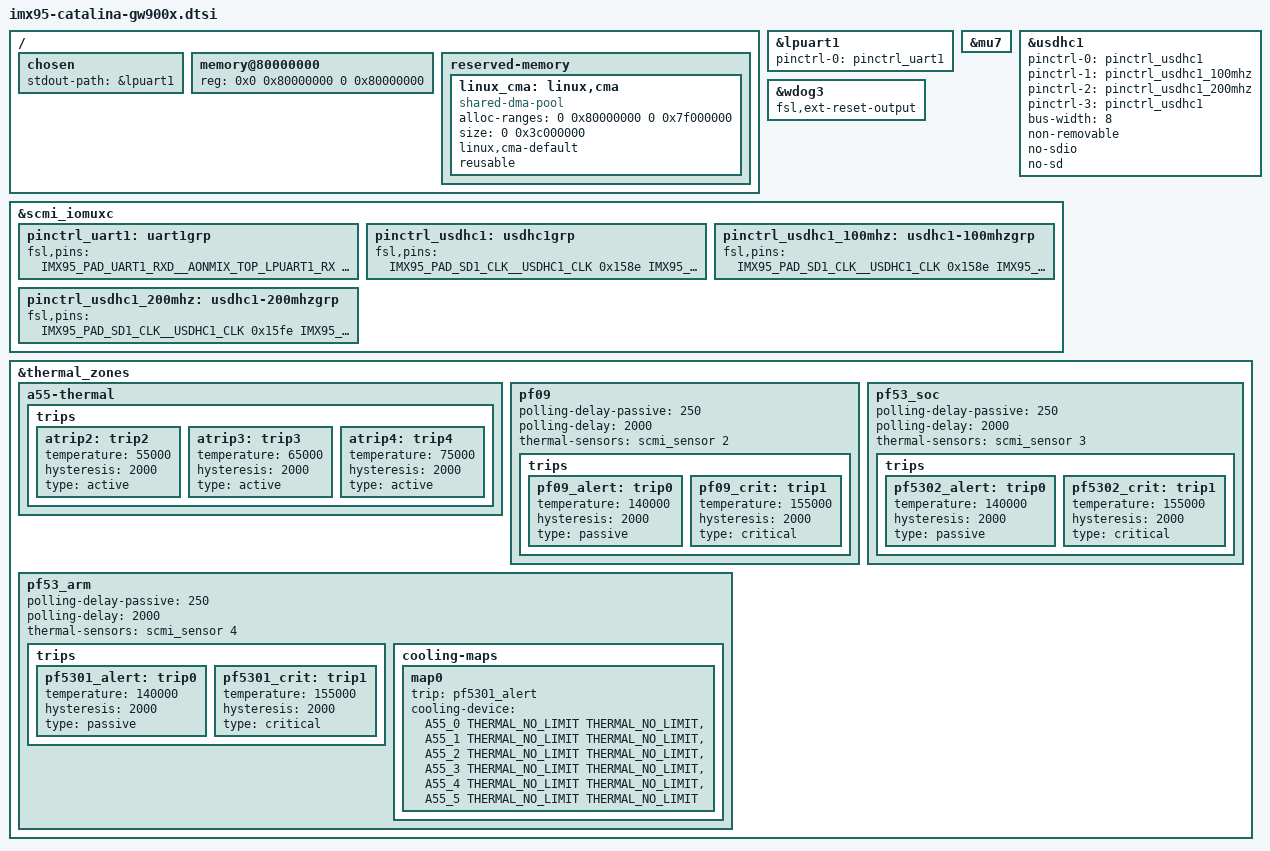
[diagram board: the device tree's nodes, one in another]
// SPDX-License-Identifier: (GPL-2.0+ OR MIT)
/*
 * Copyright 2025 Gateworks Corporation
 */

/ {
	chosen {
		stdout-path = &lpuart1;
	};

	memory@80000000 {
		device_type = "memory";
		reg = <0x0 0x80000000 0 0x80000000>;
	};

	reserved-memory {
		#address-cells = <2>;
		#size-cells = <2>;
		ranges;

		linux_cma: linux,cma {
			compatible = "shared-dma-pool";
			alloc-ranges = <0 0x80000000 0 0x7f000000>;
			size = <0 0x3c000000>;
			linux,cma-default;
			reusable;
		};
	};
};

/* console */
&lpuart1 {
	pinctrl-names = "default";
	pinctrl-0 = <&pinctrl_uart1>;
	status = "okay";
};

&mu7 {
	status = "okay";
};

/* eMMC */
&usdhc1 {
	pinctrl-names = "default", "state_100mhz", "state_200mhz", "sleep";
	pinctrl-0 = <&pinctrl_usdhc1>;
	pinctrl-1 = <&pinctrl_usdhc1_100mhz>;
	pinctrl-2 = <&pinctrl_usdhc1_200mhz>;
	pinctrl-3 = <&pinctrl_usdhc1>;
	bus-width = <8>;
	non-removable;
	no-sdio;
	no-sd;
	status = "okay";
};

&wdog3 {
	fsl,ext-reset-output;
	status = "okay";
};

&scmi_iomuxc {
	pinctrl_uart1: uart1grp {
		fsl,pins = <
			IMX95_PAD_UART1_RXD__AONMIX_TOP_LPUART1_RX      0x31e
			IMX95_PAD_UART1_TXD__AONMIX_TOP_LPUART1_TX      0x31e
		>;
	};

	pinctrl_usdhc1: usdhc1grp {
		fsl,pins = <
			IMX95_PAD_SD1_CLK__USDHC1_CLK			0x158e
			IMX95_PAD_SD1_CMD__USDHC1_CMD			0x138e
			IMX95_PAD_SD1_DATA0__USDHC1_DATA0		0x138e
			IMX95_PAD_SD1_DATA1__USDHC1_DATA1		0x138e
			IMX95_PAD_SD1_DATA2__USDHC1_DATA2		0x138e
			IMX95_PAD_SD1_DATA3__USDHC1_DATA3		0x138e
			IMX95_PAD_SD1_DATA4__USDHC1_DATA4		0x138e
			IMX95_PAD_SD1_DATA5__USDHC1_DATA5		0x138e
			IMX95_PAD_SD1_DATA6__USDHC1_DATA6		0x138e
			IMX95_PAD_SD1_DATA7__USDHC1_DATA7		0x138e
			IMX95_PAD_SD1_STROBE__USDHC1_STROBE		0x158e
		>;
	};

	pinctrl_usdhc1_100mhz: usdhc1-100mhzgrp {
		fsl,pins = <
			IMX95_PAD_SD1_CLK__USDHC1_CLK			0x158e
			IMX95_PAD_SD1_CMD__USDHC1_CMD			0x138e
			IMX95_PAD_SD1_DATA0__USDHC1_DATA0		0x138e
			IMX95_PAD_SD1_DATA1__USDHC1_DATA1		0x138e
			IMX95_PAD_SD1_DATA2__USDHC1_DATA2		0x138e
			IMX95_PAD_SD1_DATA3__USDHC1_DATA3		0x138e
			IMX95_PAD_SD1_DATA4__USDHC1_DATA4		0x138e
			IMX95_PAD_SD1_DATA5__USDHC1_DATA5		0x138e
			IMX95_PAD_SD1_DATA6__USDHC1_DATA6		0x138e
			IMX95_PAD_SD1_DATA7__USDHC1_DATA7		0x138e
			IMX95_PAD_SD1_STROBE__USDHC1_STROBE		0x158e
		>;
	};

	pinctrl_usdhc1_200mhz: usdhc1-200mhzgrp {
		fsl,pins = <
			IMX95_PAD_SD1_CLK__USDHC1_CLK			0x15fe
			IMX95_PAD_SD1_CMD__USDHC1_CMD			0x13fe
			IMX95_PAD_SD1_DATA0__USDHC1_DATA0		0x13fe
			IMX95_PAD_SD1_DATA1__USDHC1_DATA1		0x13fe
			IMX95_PAD_SD1_DATA2__USDHC1_DATA2		0x13fe
			IMX95_PAD_SD1_DATA3__USDHC1_DATA3		0x13fe
			IMX95_PAD_SD1_DATA4__USDHC1_DATA4		0x13fe
			IMX95_PAD_SD1_DATA5__USDHC1_DATA5		0x13fe
			IMX95_PAD_SD1_DATA6__USDHC1_DATA6		0x13fe
			IMX95_PAD_SD1_DATA7__USDHC1_DATA7		0x13fe
			IMX95_PAD_SD1_STROBE__USDHC1_STROBE		0x15fe
		>;
	};
};

&thermal_zones {
	a55-thermal {
		trips {
			atrip2: trip2 {
				temperature = <55000>;
				hysteresis = <2000>;
				type = "active";
			};

			atrip3: trip3 {
				temperature = <65000>;
				hysteresis = <2000>;
				type = "active";
			};

			atrip4: trip4 {
				temperature = <75000>;
				hysteresis = <2000>;
				type = "active";
			};
		};
	};

	pf09 {
		polling-delay-passive = <250>;
		polling-delay = <2000>;
		thermal-sensors = <&scmi_sensor 2>;
		trips {
			pf09_alert: trip0 {
				temperature = <140000>;
				hysteresis = <2000>;
				type = "passive";
			};

			pf09_crit: trip1 {
				temperature = <155000>;
				hysteresis = <2000>;
				type = "critical";
			};
		};
	};

	pf53_arm {
		polling-delay-passive = <250>;
		polling-delay = <2000>;
		thermal-sensors = <&scmi_sensor 4>;
		trips {
			pf5301_alert: trip0 {
				temperature = <140000>;
				hysteresis = <2000>;
				type = "passive";
			};

			pf5301_crit: trip1 {
				temperature = <155000>;
				hysteresis = <2000>;
				type = "critical";
			};
		};

		cooling-maps {
			map0 {
				trip = <&pf5301_alert>;
				cooling-device =
					<&A55_0 THERMAL_NO_LIMIT THERMAL_NO_LIMIT>,
					<&A55_1 THERMAL_NO_LIMIT THERMAL_NO_LIMIT>,
					<&A55_2 THERMAL_NO_LIMIT THERMAL_NO_LIMIT>,
					<&A55_3 THERMAL_NO_LIMIT THERMAL_NO_LIMIT>,
					<&A55_4 THERMAL_NO_LIMIT THERMAL_NO_LIMIT>,
					<&A55_5 THERMAL_NO_LIMIT THERMAL_NO_LIMIT>;
			};
		};
	};

	pf53_soc {
		polling-delay-passive = <250>;
		polling-delay = <2000>;
		thermal-sensors = <&scmi_sensor 3>;
		trips {
			pf5302_alert: trip0 {
				temperature = <140000>;
				hysteresis = <2000>;
				type = "passive";
			};

			pf5302_crit: trip1 {
				temperature = <155000>;
				hysteresis = <2000>;
				type = "critical";
			};
		};
	};
};
